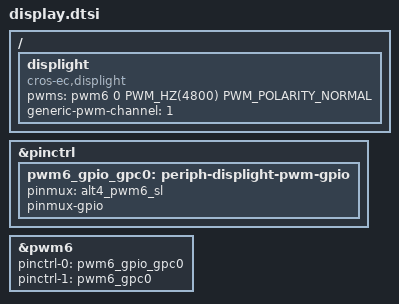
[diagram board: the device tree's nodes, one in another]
/* Copyright 2022 The ChromiumOS Authors
 * Use of this source code is governed by a BSD-style license that can be
 * found in the LICENSE file.
 */

/ {
	displight {
		compatible = "cros-ec,displight";
		pwms = <&pwm6 0 PWM_HZ(4800) PWM_POLARITY_NORMAL>;
		generic-pwm-channel = <1>;
	};
};

&pinctrl {
	/omit-if-no-ref/ pwm6_gpio_gpc0: periph-displight-pwm-gpio{
		pinmux = <&alt4_pwm6_sl>;
		pinmux-gpio;
	};
};

&pwm6 {
	status = "okay";
	pinctrl-0 = <&pwm6_gpio_gpc0>;
	pinctrl-1 = <&pwm6_gpc0>;
	pinctrl-names = "sleep", "default";
};
